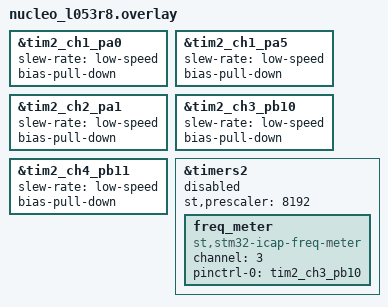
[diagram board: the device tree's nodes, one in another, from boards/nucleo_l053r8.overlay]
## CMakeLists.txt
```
# SPDX-License-Identifier: Apache-2.0

cmake_minimum_required(VERSION 3.20.0)
find_package(Zephyr REQUIRED HINTS $ENV{ZEPHYR_BASE})
project(freq_meter_stm32_icap)

FILE(GLOB app_sources src/*.c)
target_sources(app PRIVATE ${app_sources})
```

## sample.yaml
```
sample:
  name: STM32 Input Capture Frequency Meter Sensor Sample
tests:
  sample.sensor.freq_meter_stm32_icap:
    harness: sensor
    tags: sensors
    platform_allow:
      - nucleo_g474re
      - nucleo_f767zi
```

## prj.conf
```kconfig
CONFIG_LOG=y
CONFIG_SENSOR=y
CONFIG_FREQ_METER_STM32_ICAP=y
```

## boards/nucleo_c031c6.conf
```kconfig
CONFIG_FREQ_METER_STM32_ICAP_GEN=n
CONFIG_LOG_MODE_MINIMAL=y
```

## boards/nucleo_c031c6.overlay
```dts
/*
 * Copyright (c) 2024 Freedom Veiculos Eletricos
 *
 * SPDX-License-Identifier: Apache-2.0
 */

&tim3_ch2_pb5 {
	slew-rate = "low-speed";
	bias-pull-down;
};

&timers3 {
	st,prescaler = <8192>;
	status = "disabled";

	freq_meter: freq_meter {
		compatible = "st,stm32-icap-freq-meter";
		status = "okay";

		channel = <2>;
		pinctrl-0 = <&tim3_ch2_pb5>;
		pinctrl-names = "default";
	};
};
```

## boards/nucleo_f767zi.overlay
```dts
/*
 * Copyright (c) 2024 Freedom Veiculos Eletricos
 *
 * SPDX-License-Identifier: Apache-2.0
 */

&tim1_ch1_pe9 {
	slew-rate = "low-speed";
	bias-pull-down;
};

&timers1 {
	st,prescaler = <8192>;
	status = "disabled";

	freq_meter: freq_meter {
		compatible = "st,stm32-icap-freq-meter";
		status = "okay";

		channel = <1>;
		pinctrl-0 = <&tim1_ch1_pe9>;
		pinctrl-names = "default";

		dmas = <&dma2 1 6 ( STM32_DMA_PERIPH_RX  | STM32_DMA_PRIORITY_HIGH
				  | STM32_DMA_MEM_32BITS | STM32_DMA_PERIPH_32BITS
				  | STM32_DMA_MODE_CYCLIC) STM32_DMA_FIFO_FULL>;
		dma-names = "cc";
	};
};

&timers2 {
	status = "disabled";
	/* GEN is on PA0 */
};

&dma2 {
	status = "okay";
};
```

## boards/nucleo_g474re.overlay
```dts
/*
 * Copyright (c) 2024 Freedom Veiculos Eletricos
 *
 * SPDX-License-Identifier: Apache-2.0
 */

&tim1_ch1_pa8 {
	slew-rate = "low-speed";
	bias-pull-down;
};

&timers1 {
	st,prescaler = <8192>;
	status = "disabled";

	freq_meter: freq_meter {
		compatible = "st,stm32-icap-freq-meter";
		status = "okay";

		pinctrl-0 = <&tim1_ch1_pa8>;
		pinctrl-names = "default";
/*
		dmas = <&dmamux1 1 42 ( STM32_DMA_PERIPH_RX  | STM32_DMA_PRIORITY_HIGH
				      | STM32_DMA_MEM_32BITS | STM32_DMA_PERIPH_32BITS
				      | STM32_DMA_MODE_CYCLIC)>;
		dma-names = "cc";
*/
	};
};

&timers2 {
	status = "disabled";
};

&dma1 {
	status = "okay";
};

&dmamux1 {
	status = "okay";
};
```

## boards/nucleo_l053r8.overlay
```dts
/*
 * Copyright (c) 2024 Freedom Veiculos Eletricos
 *
 * SPDX-License-Identifier: Apache-2.0
 */

&tim2_ch1_pa0 {
	slew-rate = "low-speed";
	bias-pull-down;
};

&tim2_ch1_pa5 {
	slew-rate = "low-speed";
	bias-pull-down;
};

&tim2_ch2_pa1 {
	slew-rate = "low-speed";
	bias-pull-down;
};

&tim2_ch3_pb10 {
	slew-rate = "low-speed";
	bias-pull-down;
};

&tim2_ch4_pb11 {
	slew-rate = "low-speed";
	bias-pull-down;
};

&timers2 {
	st,prescaler = <8192>;
	status = "disabled";

	freq_meter: freq_meter {
		compatible = "st,stm32-icap-freq-meter";
		status = "okay";

		channel = <3>;
		pinctrl-0 = <&tim2_ch3_pb10>;
		pinctrl-names = "default";
	};
};
```

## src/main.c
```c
/*
 * Copyright (c) 2024 Freedom Veiculos Eletricos
 *
 * SPDX-License-Identifier: Apache-2.0
 */

#include <zephyr/kernel.h>
#include <zephyr/drivers/sensor.h>
#include <stdio.h>

int main(void)
{
	const struct device *const dev = DEVICE_DT_GET(DT_NODELABEL(freq_meter));
	struct sensor_value freq, rpm;

	if (dev == NULL || !device_is_ready(dev)) {
		printf("Could not get freq_meter device\n");
		return 0;
	}

	while (1) {
		sensor_sample_fetch(dev);
		sensor_channel_get(dev, SENSOR_CHAN_FREQUENCY, &freq);
		sensor_channel_get(dev, SENSOR_CHAN_RPM, &rpm);

		printf("Freq=%dHz\tRPM=%d\n", freq.val1, rpm.val1);

		k_sleep(K_MSEC(1000));
	}
	return 0;
}
```
